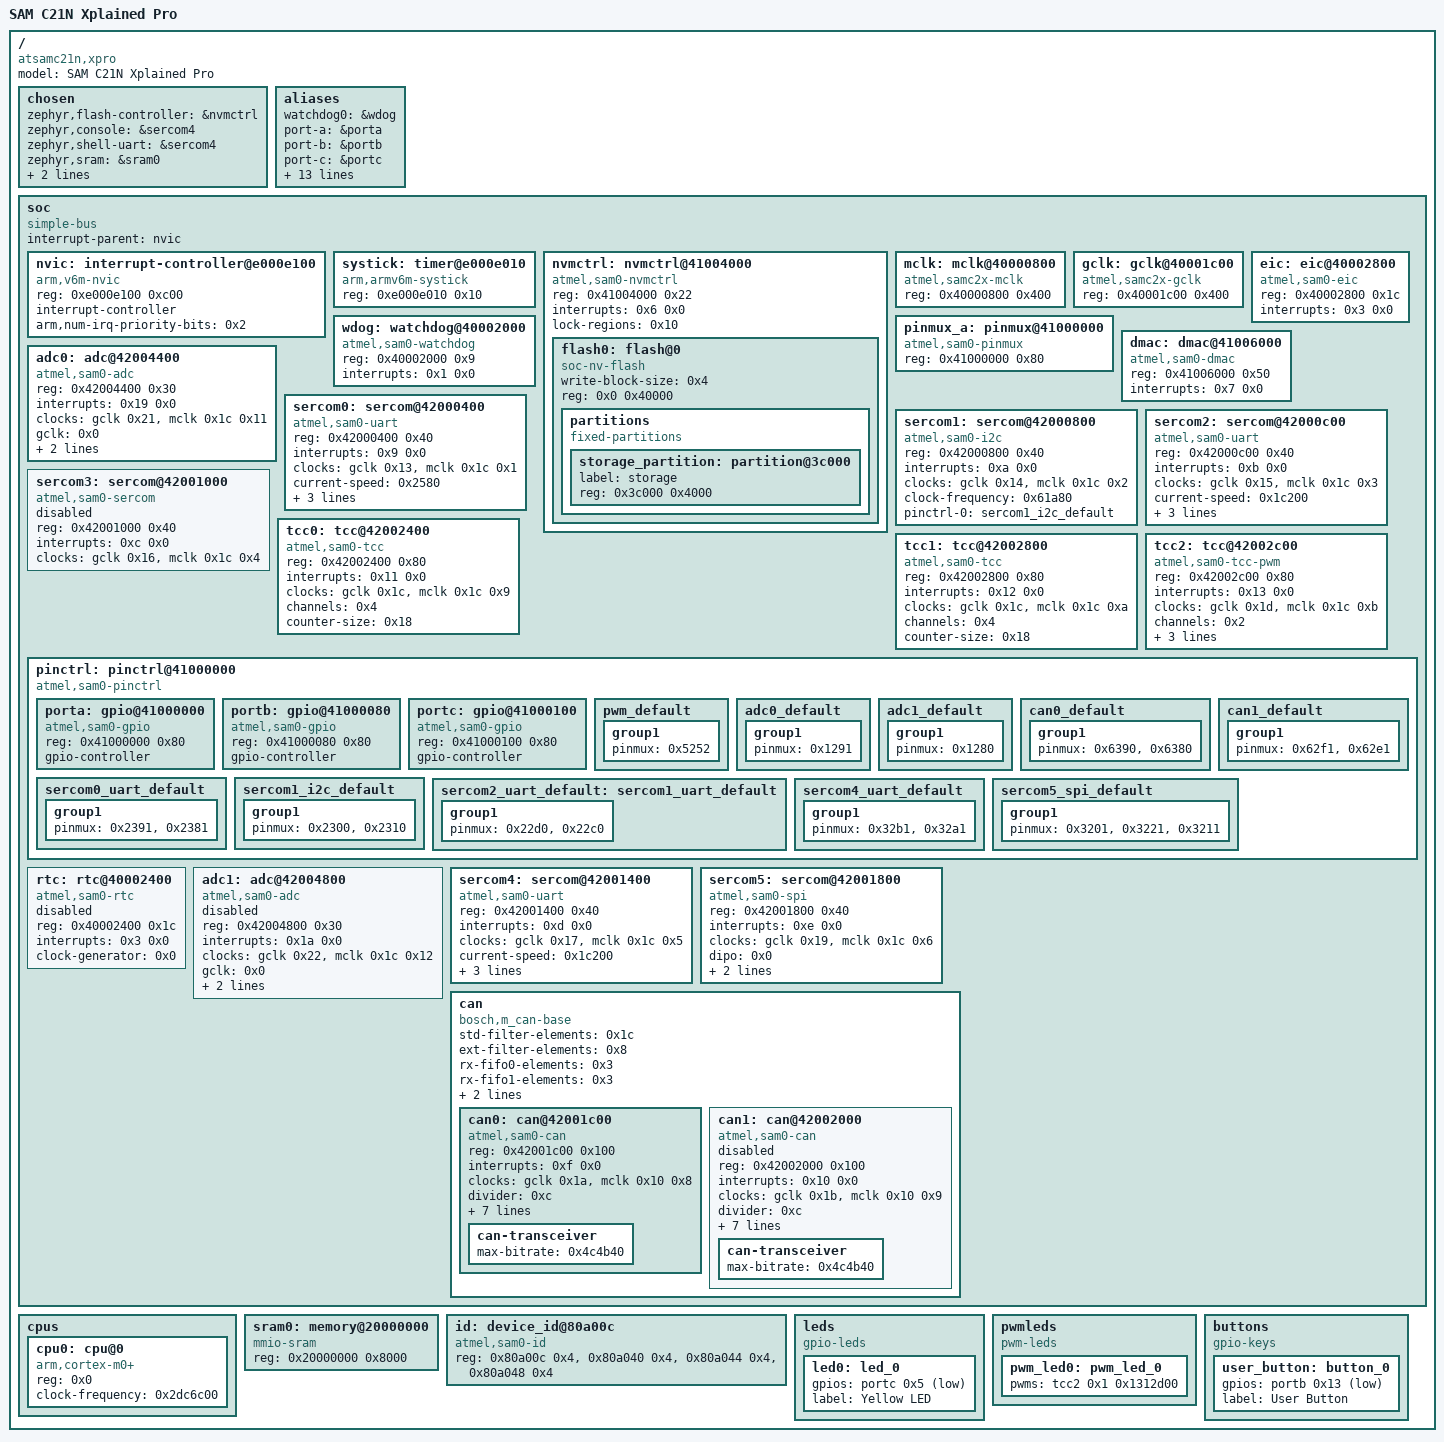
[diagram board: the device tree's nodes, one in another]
/dts-v1/;

/ {
	#address-cells = < 0x1 >;
	#size-cells = < 0x1 >;
	model = "SAM C21N Xplained Pro";
	compatible = "atsamc21n,xpro", "atmel,samc21n18a", "atmel,samc21";
	chosen {
		zephyr,flash-controller = &nvmctrl;
		zephyr,console = &sercom4;
		zephyr,shell-uart = &sercom4;
		zephyr,sram = &sram0;
		zephyr,flash = &flash0;
		zephyr,canbus = &can0;
	};
	aliases {
		watchdog0 = &wdog;
		port-a = &porta;
		port-b = &portb;
		port-c = &portc;
		sercom-0 = &sercom0;
		sercom-1 = &sercom1;
		sercom-2 = &sercom2;
		sercom-3 = &sercom3;
		tcc-0 = &tcc0;
		tcc-1 = &tcc1;
		tcc-2 = &tcc2;
		sercom-4 = &sercom4;
		sercom-5 = &sercom5;
		led0 = &led0;
		pwm-led0 = &pwm_led0;
		sw0 = &user_button;
		i2c-0 = &sercom1;
	};
	soc {
		#address-cells = < 0x1 >;
		#size-cells = < 0x1 >;
		compatible = "simple-bus";
		interrupt-parent = < &nvic >;
		ranges;
		nvic: interrupt-controller@e000e100 {
			#address-cells = < 0x1 >;
			compatible = "arm,v6m-nvic";
			reg = < 0xe000e100 0xc00 >;
			interrupt-controller;
			#interrupt-cells = < 0x2 >;
			arm,num-irq-priority-bits = < 0x2 >;
			phandle = < 0x1 >;
		};
		systick: timer@e000e010 {
			compatible = "arm,armv6m-systick";
			reg = < 0xe000e010 0x10 >;
		};
		nvmctrl: nvmctrl@41004000 {
			compatible = "atmel,sam0-nvmctrl";
			reg = < 0x41004000 0x22 >;
			interrupts = < 0x6 0x0 >;
			lock-regions = < 0x10 >;
			#address-cells = < 0x1 >;
			#size-cells = < 0x1 >;
			flash0: flash@0 {
				compatible = "soc-nv-flash";
				write-block-size = < 0x4 >;
				reg = < 0x0 0x40000 >;
				partitions {
					compatible = "fixed-partitions";
					#address-cells = < 0x1 >;
					#size-cells = < 0x1 >;
					storage_partition: partition@3c000 {
						label = "storage";
						reg = < 0x3c000 0x4000 >;
					};
				};
			};
		};
		mclk: mclk@40000800 {
			compatible = "atmel,samc2x-mclk";
			reg = < 0x40000800 0x400 >;
			#clock-cells = < 0x2 >;
			phandle = < 0x3 >;
		};
		gclk: gclk@40001c00 {
			compatible = "atmel,samc2x-gclk";
			reg = < 0x40001c00 0x400 >;
			#clock-cells = < 0x1 >;
			phandle = < 0x2 >;
		};
		eic: eic@40002800 {
			compatible = "atmel,sam0-eic";
			reg = < 0x40002800 0x1c >;
			interrupts = < 0x3 0x0 >;
		};
		pinmux_a: pinmux@41000000 {
			compatible = "atmel,sam0-pinmux";
			reg = < 0x41000000 0x80 >;
		};
		wdog: watchdog@40002000 {
			compatible = "atmel,sam0-watchdog";
			reg = < 0x40002000 0x9 >;
			interrupts = < 0x1 0x0 >;
		};
		dmac: dmac@41006000 {
			compatible = "atmel,sam0-dmac";
			reg = < 0x41006000 0x50 >;
			interrupts = < 0x7 0x0 >;
			#dma-cells = < 0x2 >;
		};
		adc0: adc@42004400 {
			compatible = "atmel,sam0-adc";
			status = "okay";
			reg = < 0x42004400 0x30 >;
			interrupts = < 0x19 0x0 >;
			interrupt-names = "resrdy";
			clocks = < &gclk 0x21 >, < &mclk 0x1c 0x11 >;
			clock-names = "GCLK", "MCLK";
			gclk = < 0x0 >;
			prescaler = < 0x4 >;
			#io-channel-cells = < 0x1 >;
			pinctrl-0 = < &adc0_default >;
			pinctrl-names = "default";
		};
		sercom0: sercom@42000400 {
			compatible = "atmel,sam0-uart";
			reg = < 0x42000400 0x40 >;
			interrupts = < 0x9 0x0 >;
			clocks = < &gclk 0x13 >, < &mclk 0x1c 0x1 >;
			clock-names = "GCLK", "MCLK";
			status = "okay";
			current-speed = < 0x2580 >;
			rxpo = < 0x1 >;
			txpo = < 0x0 >;
			pinctrl-0 = < &sercom0_uart_default >;
			pinctrl-names = "default";
		};
		sercom1: sercom@42000800 {
			compatible = "atmel,sam0-i2c";
			reg = < 0x42000800 0x40 >;
			interrupts = < 0xa 0x0 >;
			clocks = < &gclk 0x14 >, < &mclk 0x1c 0x2 >;
			clock-names = "GCLK", "MCLK";
			status = "okay";
			clock-frequency = < 0x61a80 >;
			#address-cells = < 0x1 >;
			#size-cells = < 0x0 >;
			pinctrl-0 = < &sercom1_i2c_default >;
			pinctrl-names = "default";
		};
		sercom2: sercom@42000c00 {
			compatible = "atmel,sam0-uart";
			reg = < 0x42000c00 0x40 >;
			interrupts = < 0xb 0x0 >;
			clocks = < &gclk 0x15 >, < &mclk 0x1c 0x3 >;
			clock-names = "GCLK", "MCLK";
			status = "okay";
			current-speed = < 0x1c200 >;
			rxpo = < 0x1 >;
			txpo = < 0x0 >;
			pinctrl-0 = < &sercom2_uart_default >;
			pinctrl-names = "default";
		};
		sercom3: sercom@42001000 {
			compatible = "atmel,sam0-sercom";
			reg = < 0x42001000 0x40 >;
			interrupts = < 0xc 0x0 >;
			clocks = < &gclk 0x16 >, < &mclk 0x1c 0x4 >;
			clock-names = "GCLK", "MCLK";
			status = "disabled";
		};
		tcc0: tcc@42002400 {
			compatible = "atmel,sam0-tcc";
			reg = < 0x42002400 0x80 >;
			interrupts = < 0x11 0x0 >;
			clocks = < &gclk 0x1c >, < &mclk 0x1c 0x9 >;
			clock-names = "GCLK", "MCLK";
			channels = < 0x4 >;
			counter-size = < 0x18 >;
		};
		tcc1: tcc@42002800 {
			compatible = "atmel,sam0-tcc";
			reg = < 0x42002800 0x80 >;
			interrupts = < 0x12 0x0 >;
			clocks = < &gclk 0x1c >, < &mclk 0x1c 0xa >;
			clock-names = "GCLK", "MCLK";
			channels = < 0x4 >;
			counter-size = < 0x18 >;
		};
		tcc2: tcc@42002c00 {
			compatible = "atmel,sam0-tcc-pwm";
			reg = < 0x42002c00 0x80 >;
			interrupts = < 0x13 0x0 >;
			clocks = < &gclk 0x1d >, < &mclk 0x1c 0xb >;
			clock-names = "GCLK", "MCLK";
			channels = < 0x2 >;
			counter-size = < 0x10 >;
			status = "okay";
			prescaler = < 0x100 >;
			#pwm-cells = < 0x2 >;
			pinctrl-0 = < &pwm_default >;
			pinctrl-names = "default";
			phandle = < 0xf >;
		};
		pinctrl: pinctrl@41000000 {
			compatible = "atmel,sam0-pinctrl";
			#address-cells = < 0x1 >;
			#size-cells = < 0x1 >;
			ranges = < 0x41000000 0x41000000 0x180 >;
			porta: gpio@41000000 {
				compatible = "atmel,sam0-gpio";
				reg = < 0x41000000 0x80 >;
				gpio-controller;
				#gpio-cells = < 0x2 >;
				#atmel,pin-cells = < 0x2 >;
			};
			portb: gpio@41000080 {
				compatible = "atmel,sam0-gpio";
				reg = < 0x41000080 0x80 >;
				gpio-controller;
				#gpio-cells = < 0x2 >;
				#atmel,pin-cells = < 0x2 >;
				phandle = < 0x10 >;
			};
			portc: gpio@41000100 {
				compatible = "atmel,sam0-gpio";
				reg = < 0x41000100 0x80 >;
				gpio-controller;
				#gpio-cells = < 0x2 >;
				#atmel,pin-cells = < 0x2 >;
				phandle = < 0xe >;
			};
			pwm_default: pwm_default {
				phandle = < 0x8 >;
				group1 {
					pinmux = < 0x5252 >;
				};
			};
			adc0_default: adc0_default {
				phandle = < 0x4 >;
				group1 {
					pinmux = < 0x1291 >;
				};
			};
			adc1_default: adc1_default {
				phandle = < 0x9 >;
				group1 {
					pinmux = < 0x1280 >;
				};
			};
			can0_default: can0_default {
				phandle = < 0xc >;
				group1 {
					pinmux = < 0x6390 >, < 0x6380 >;
				};
			};
			can1_default: can1_default {
				phandle = < 0xd >;
				group1 {
					pinmux = < 0x62f1 >, < 0x62e1 >;
				};
			};
			sercom0_uart_default: sercom0_uart_default {
				phandle = < 0x5 >;
				group1 {
					pinmux = < 0x2391 >, < 0x2381 >;
				};
			};
			sercom1_i2c_default: sercom1_i2c_default {
				phandle = < 0x6 >;
				group1 {
					pinmux = < 0x2300 >, < 0x2310 >;
				};
			};
			sercom2_uart_default: sercom1_uart_default {
				phandle = < 0x7 >;
				group1 {
					pinmux = < 0x22d0 >, < 0x22c0 >;
				};
			};
			sercom4_uart_default: sercom4_uart_default {
				phandle = < 0xa >;
				group1 {
					pinmux = < 0x32b1 >, < 0x32a1 >;
				};
			};
			sercom5_spi_default: sercom5_spi_default {
				phandle = < 0xb >;
				group1 {
					pinmux = < 0x3201 >, < 0x3221 >, < 0x3211 >;
				};
			};
		};
		rtc: rtc@40002400 {
			compatible = "atmel,sam0-rtc";
			reg = < 0x40002400 0x1c >;
			interrupts = < 0x3 0x0 >;
			clock-generator = < 0x0 >;
			status = "disabled";
		};
		adc1: adc@42004800 {
			compatible = "atmel,sam0-adc";
			status = "disabled";
			reg = < 0x42004800 0x30 >;
			interrupts = < 0x1a 0x0 >;
			interrupt-names = "resrdy";
			clocks = < &gclk 0x22 >, < &mclk 0x1c 0x12 >;
			clock-names = "GCLK", "MCLK";
			gclk = < 0x0 >;
			prescaler = < 0x4 >;
			#io-channel-cells = < 0x1 >;
			pinctrl-0 = < &adc1_default >;
			pinctrl-names = "default";
		};
		sercom4: sercom@42001400 {
			compatible = "atmel,sam0-uart";
			reg = < 0x42001400 0x40 >;
			interrupts = < 0xd 0x0 >;
			clocks = < &gclk 0x17 >, < &mclk 0x1c 0x5 >;
			clock-names = "GCLK", "MCLK";
			status = "okay";
			current-speed = < 0x1c200 >;
			rxpo = < 0x3 >;
			txpo = < 0x1 >;
			pinctrl-0 = < &sercom4_uart_default >;
			pinctrl-names = "default";
		};
		sercom5: sercom@42001800 {
			compatible = "atmel,sam0-spi";
			reg = < 0x42001800 0x40 >;
			interrupts = < 0xe 0x0 >;
			clocks = < &gclk 0x19 >, < &mclk 0x1c 0x6 >;
			clock-names = "GCLK", "MCLK";
			status = "okay";
			dipo = < 0x0 >;
			dopo = < 0x2 >;
			#address-cells = < 0x1 >;
			#size-cells = < 0x0 >;
			pinctrl-0 = < &sercom5_spi_default >;
			pinctrl-names = "default";
		};
		can {
			compatible = "bosch,m_can-base";
			#address-cells = < 0x1 >;
			#size-cells = < 0x1 >;
			std-filter-elements = < 0x1c >;
			ext-filter-elements = < 0x8 >;
			rx-fifo0-elements = < 0x3 >;
			rx-fifo1-elements = < 0x3 >;
			rx-buffer-elements = < 0x0 >;
			tx-buffer-elements = < 0x1 >;
			can0: can@42001c00 {
				compatible = "atmel,sam0-can";
				reg = < 0x42001c00 0x100 >;
				interrupts = < 0xf 0x0 >;
				interrupt-names = "LINE_0";
				clocks = < &gclk 0x1a >, < &mclk 0x10 0x8 >;
				clock-names = "GCLK", "MCLK";
				divider = < 0xc >;
				sjw = < 0x1 >;
				sample-point = < 0x36b >;
				sjw-data = < 0x1 >;
				sample-point-data = < 0x36b >;
				status = "okay";
				pinctrl-0 = < &can0_default >;
				pinctrl-names = "default";
				bus-speed = < 0x1e848 >;
				bus-speed-data = < 0xf4240 >;
				can-transceiver {
					max-bitrate = < 0x4c4b40 >;
				};
			};
			can1: can@42002000 {
				compatible = "atmel,sam0-can";
				reg = < 0x42002000 0x100 >;
				interrupts = < 0x10 0x0 >;
				interrupt-names = "LINE_0";
				clocks = < &gclk 0x1b >, < &mclk 0x10 0x9 >;
				clock-names = "GCLK", "MCLK";
				divider = < 0xc >;
				sjw = < 0x1 >;
				sample-point = < 0x36b >;
				sjw-data = < 0x1 >;
				sample-point-data = < 0x36b >;
				status = "disabled";
				pinctrl-0 = < &can1_default >;
				pinctrl-names = "default";
				bus-speed = < 0x1e848 >;
				bus-speed-data = < 0xf4240 >;
				can-transceiver {
					max-bitrate = < 0x4c4b40 >;
				};
			};
		};
	};
	cpus {
		#address-cells = < 0x1 >;
		#size-cells = < 0x0 >;
		cpu0: cpu@0 {
			device_type = "cpu";
			compatible = "arm,cortex-m0+";
			reg = < 0x0 >;
			clock-frequency = < 0x2dc6c00 >;
		};
	};
	sram0: memory@20000000 {
		compatible = "mmio-sram";
		reg = < 0x20000000 0x8000 >;
	};
	id: device_id@80a00c {
		compatible = "atmel,sam0-id";
		reg = < 0x80a00c 0x4 >, < 0x80a040 0x4 >, < 0x80a044 0x4 >, < 0x80a048 0x4 >;
	};
	leds {
		compatible = "gpio-leds";
		led0: led_0 {
			gpios = < &portc 0x5 0x1 >;
			label = "Yellow LED";
		};
	};
	pwmleds {
		compatible = "pwm-leds";
		pwm_led0: pwm_led_0 {
			pwms = < &tcc2 0x1 0x1312d00 >;
		};
	};
	buttons {
		compatible = "gpio-keys";
		user_button: button_0 {
			gpios = < &portb 0x13 0x11 >;
			label = "User Button";
		};
	};
};
